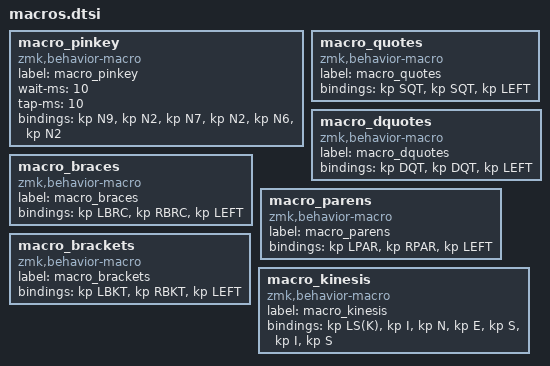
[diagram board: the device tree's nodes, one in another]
  macro_pinkey: macro_pinkey {
    compatible = "zmk,behavior-macro";
    label = "macro_pinkey";
	wait-ms = <10>;
	tap-ms = <10>;
    #binding-cells = <0>;
    bindings = <&kp N9>, <&kp N2>, <&kp N7>, <&kp N2>, <&kp N6>, <&kp N2>;
  };
  macro_quotes: macro_quotes {
    compatible = "zmk,behavior-macro";
    label = "macro_quotes";
    #binding-cells = <0>;
    bindings = <&kp SQT>, <&kp SQT>, <&kp LEFT>;
  };
  macro_dquotes: macro_dquotes {
    compatible = "zmk,behavior-macro";
    label = "macro_dquotes";
    #binding-cells = <0>;
    bindings = <&kp DQT>, <&kp DQT>, <&kp LEFT>;
  };
  macro_braces: macro_braces {
    compatible = "zmk,behavior-macro";
    label = "macro_braces";
    #binding-cells = <0>;
    bindings = <&kp LBRC>, <&kp RBRC>, <&kp LEFT>;
  };
  macro_parens: macro_parens {
    compatible = "zmk,behavior-macro";
    label = "macro_parens";
    #binding-cells = <0>;
    bindings = <&kp LPAR>, <&kp RPAR>, <&kp LEFT>;
  };
  macro_brackets: macro_brackets {
    compatible = "zmk,behavior-macro";
    label = "macro_brackets";
    #binding-cells = <0>;
    bindings = <&kp LBKT>, <&kp RBKT>, <&kp LEFT>;
  };
  macro_kinesis: macro_kinesis {
    compatible = "zmk,behavior-macro";
    label = "macro_kinesis";
    #binding-cells = <0>;
    bindings = <&kp LS(K)>, <&kp I>, <&kp N>, <&kp E>, <&kp S>, <&kp I>, <&kp S>;
  };
